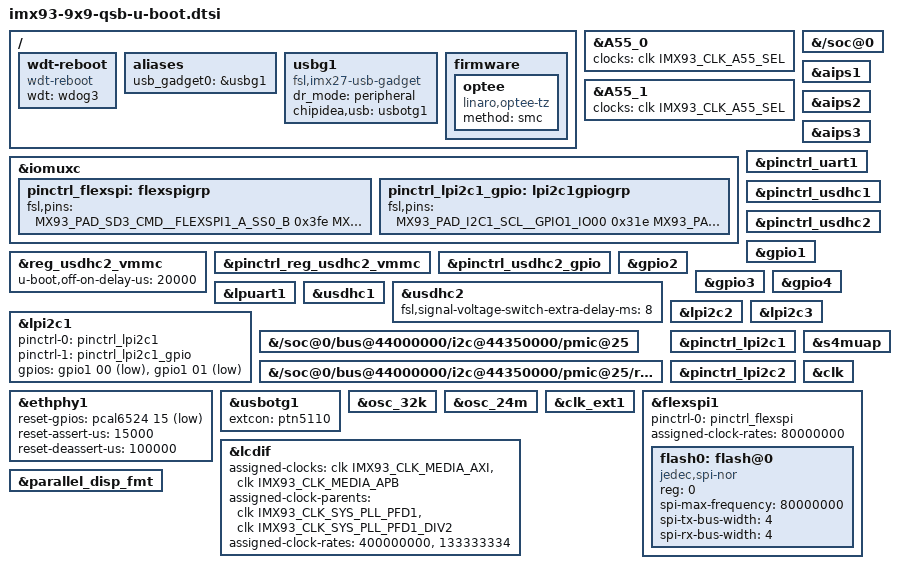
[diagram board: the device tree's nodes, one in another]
// SPDX-License-Identifier: GPL-2.0+
/*
 * Copyright 2024 NXP
 */

#include "imx93-u-boot.dtsi"
#include "imx93-9x9-qsb-tianma-wvga-panel.dtsi"

/ {
	wdt-reboot {
		compatible = "wdt-reboot";
		wdt = <&wdog3>;
		bootph-pre-ram;
		bootph-some-ram;
	};

	aliases {
		usb_gadget0 = &usbg1;
	};

	usbg1: usbg1 {
		compatible = "fsl,imx27-usb-gadget";
		dr_mode = "peripheral";
		chipidea,usb = <&usbotg1>;
		status = "okay";
	};

	firmware {
		optee {
			compatible = "linaro,optee-tz";
			method = "smc";
		};
	};
};

&A55_0 {
	clocks = <&clk IMX93_CLK_A55_SEL>;
};

&A55_1 {
	clocks = <&clk IMX93_CLK_A55_SEL>;
};

&{/soc@0} {
	bootph-all;
	bootph-pre-ram;
};

&aips1 {
	bootph-pre-ram;
	bootph-all;
};

&aips2 {
	bootph-pre-ram;
	bootph-some-ram;
};

&aips3 {
	bootph-pre-ram;
	bootph-some-ram;
};

&iomuxc {
	bootph-pre-ram;
	bootph-some-ram;

	pinctrl_flexspi: flexspigrp {
		fsl,pins = <
			MX93_PAD_SD3_CMD__FLEXSPI1_A_SS0_B	0x3fe
			MX93_PAD_SD3_CLK__FLEXSPI1_A_SCLK	0x3fe
			MX93_PAD_SD3_DATA0__FLEXSPI1_A_DATA00	0x3fe
			MX93_PAD_SD3_DATA1__FLEXSPI1_A_DATA01	0x3fe
			MX93_PAD_SD3_DATA2__FLEXSPI1_A_DATA02	0x3fe
			MX93_PAD_SD3_DATA3__FLEXSPI1_A_DATA03	0x3fe
		>;
	};

	pinctrl_lpi2c1_gpio: lpi2c1gpiogrp {
		fsl,pins = <
			MX93_PAD_I2C1_SCL__GPIO1_IO00		0x31e
			MX93_PAD_I2C1_SDA__GPIO1_IO01		0x31e
		>;
	};

};

&reg_usdhc2_vmmc {
	u-boot,off-on-delay-us = <20000>;
	bootph-pre-ram;
	bootph-some-ram;
};

&pinctrl_reg_usdhc2_vmmc {
	bootph-pre-ram;
	bootph-some-ram;
};

&pinctrl_uart1 {
	bootph-pre-ram;
	bootph-some-ram;
};

&pinctrl_usdhc1 {
	bootph-pre-ram;
};

&pinctrl_usdhc2_gpio {
	bootph-pre-ram;
	bootph-some-ram;
};

&pinctrl_usdhc2 {
	bootph-pre-ram;
	bootph-some-ram;
};

&gpio1 {
	bootph-pre-ram;
	bootph-some-ram;
};

&gpio2 {
	bootph-pre-ram;
	bootph-some-ram;
};

&gpio3 {
	bootph-pre-ram;
	bootph-some-ram;
};

&gpio4 {
	bootph-pre-ram;
	bootph-some-ram;
};

&lpuart1 {
	bootph-pre-ram;
	bootph-some-ram;
};

&usdhc1 {
	bootph-pre-ram;
	bootph-some-ram;
};

&usdhc2 {
	bootph-pre-ram;
	bootph-some-ram;
	fsl,signal-voltage-switch-extra-delay-ms = <8>;
};

&lpi2c1 {
	bootph-pre-ram;
	bootph-some-ram;
	pinctrl-names = "default", "gpio";
	pinctrl-0 = <&pinctrl_lpi2c1>;
	pinctrl-1 = <&pinctrl_lpi2c1_gpio>;
	gpios = <&gpio1 00 GPIO_ACTIVE_LOW>,
		<&gpio1 01 GPIO_ACTIVE_LOW>;
};

&lpi2c2 {
	bootph-pre-ram;
	bootph-some-ram;
};

&lpi2c3 {
	bootph-pre-ram;
	bootph-some-ram;
};

&{/soc@0/bus@44000000/i2c@44350000/pmic@25} {
	bootph-pre-ram;
	bootph-some-ram;
};

&{/soc@0/bus@44000000/i2c@44350000/pmic@25/regulators} {
	bootph-pre-ram;
	bootph-some-ram;
};

&pinctrl_lpi2c1 {
	bootph-pre-ram;
	bootph-some-ram;
};

&pinctrl_lpi2c2 {
	bootph-pre-ram;
	bootph-some-ram;
};

&ethphy1 {
	reset-gpios = <&pcal6524 15 GPIO_ACTIVE_LOW>;
	reset-assert-us = <15000>;
	reset-deassert-us = <100000>;
};

&usbotg1 {
	status = "okay";
	extcon = <&ptn5110>;
};

&s4muap {
	bootph-pre-ram;
	bootph-some-ram;
	status = "okay";
};

&clk {
	bootph-all;
	bootph-pre-ram;
	/delete-property/ assigned-clocks;
	/delete-property/ assigned-clock-rates;
	/delete-property/ assigned-clock-parents;
};

&osc_32k {
	bootph-all;
	bootph-pre-ram;
};

&osc_24m {
	bootph-all;
	bootph-pre-ram;
};

&clk_ext1 {
	bootph-all;
	bootph-pre-ram;
};

&flexspi1 {
	pinctrl-names = "default";
	pinctrl-0 = <&pinctrl_flexspi>;
	assigned-clock-rates = <80000000>;
	status = "okay";

	flash0: flash@0 {
		reg = <0>;
		#address-cells = <1>;
		#size-cells = <1>;
		compatible = "jedec,spi-nor";
		spi-max-frequency = <80000000>;
		spi-tx-bus-width = <4>;
		spi-rx-bus-width = <4>;
	};
};

&lcdif {
	assigned-clocks = <&clk IMX93_CLK_MEDIA_AXI>, <&clk IMX93_CLK_MEDIA_APB>;
	assigned-clock-parents = <&clk IMX93_CLK_SYS_PLL_PFD1>, <&clk IMX93_CLK_SYS_PLL_PFD1_DIV2>;
	assigned-clock-rates = <400000000>, <133333334>;
};

&parallel_disp_fmt {
	/delete-property/ power-domains;
};
